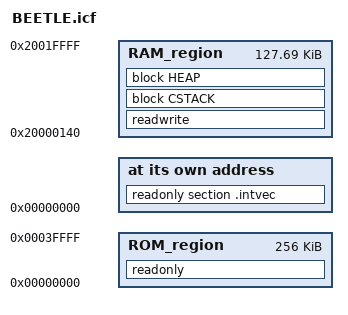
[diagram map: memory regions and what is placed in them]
/*
 * BEETLE CMSIS Library
 */
/*
 * Copyright (c) 2009-2016 ARM Limited. All rights reserved.
 *
 * SPDX-License-Identifier: Apache-2.0
 *
 * Licensed under the Apache License, Version 2.0 (the License) you may
 * not use this file except in compliance with the License.
 * You may obtain a copy of the License at
 *
 * http://www.apache.org/licenses/LICENSE-2.0
 *
 * Unless required by applicable law or agreed to in writing, software
 * distributed under the License is distributed on an AS IS BASIS, WITHOUT
 * WARRANTIES OR CONDITIONS OF ANY KIND, either express or implied.
 * See the License for the specific language governing permissions and
 * limitations under the License.
 */
/*###ICF### Section handled by ICF editor, don't touch! ****/
/*-Editor annotation file-*/
/* IcfEditorFile="$TOOLKIT_DIR$\config\ide\IcfEditor\cortex_v1_0.xml" */
/*-Specials-*/
define symbol __ICFEDIT_intvec_start__ = 0x00000000;
/*-Memory Regions-*/
define symbol __ICFEDIT_region_ROM_start__    = 0x00000000;
define symbol __ICFEDIT_region_ROM_end__      = 0x0003FFFF;
define symbol __ICFEDIT_region_RAM_start__    = 0x20000140;
define symbol __ICFEDIT_region_RAM_end__      = 0x2001FFFF;
/*-Sizes-*/
/* Heap and Stack size */
define symbol __ICFEDIT_size_cstack__ = 0x1000;
define symbol __ICFEDIT_size_heap__   = 0x4000;
/**** End of ICF editor section. ###ICF###*/

define memory mem with size = 4G;
define region ROM_region      = mem:[from __ICFEDIT_region_ROM_start__   to __ICFEDIT_region_ROM_end__];
define region RAM_region      = mem:[from __ICFEDIT_region_RAM_start__   to __ICFEDIT_region_RAM_end__];

initialize by copy { readwrite };
do not initialize  { section .noinit };

define block CSTACK    with alignment = 8, size = __ICFEDIT_size_cstack__   { };
define block HEAP      with alignment = 8, size = __ICFEDIT_size_heap__     { };

place at address mem:__ICFEDIT_intvec_start__ { readonly section .intvec };
place in ROM_region   { readonly };
place in RAM_region   { readwrite,
                        block CSTACK, block HEAP };
